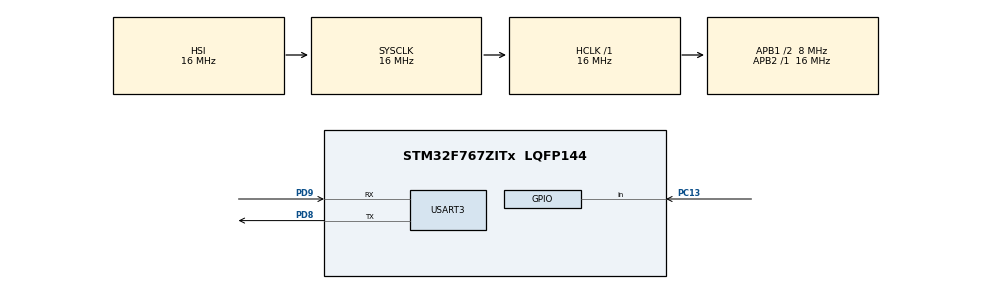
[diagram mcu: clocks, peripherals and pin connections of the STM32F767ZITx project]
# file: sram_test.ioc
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Mcu.Family=STM32F7
Mcu.Name=STM32F767ZITx
Mcu.Package=LQFP144
NVIC.PriorityGroup=NVIC_PRIORITYGROUP_4
PC13.Signal=GPIO_Input
PD8.Mode=Asynchronous
PD8.Signal=USART3_TX
PD9.Mode=Asynchronous
PD9.Signal=USART3_RX
ProjectManager.HeapSize=0x200
ProjectManager.StackSize=0x400
ProjectManager.TargetToolchain=MDK-ARM V5
RCC.48MHZClocksFreq_Value=24000000
RCC.AHBFreq_Value=16000000
RCC.APB1CLKDivider=RCC_HCLK_DIV2
RCC.APB1Freq_Value=8000000
RCC.APB1TimFreq_Value=16000000
RCC.APB2Freq_Value=16000000
RCC.APB2TimFreq_Value=16000000
RCC.CortexFreq_Value=16000000
RCC.HCLKFreq_Value=16000000
RCC.HSE_VALUE=16000000
RCC.HSI_VALUE=16000000
RCC.LSE_VALUE=32768
RCC.PLLMUL=RCC_PLL_MUL9
RCC.PRESCALERUSB=RCC_USBCLKSOURCE_PLL_DIV1_5
RCC.SYSCLKFreq_VALUE=16000000
RCC.SYSCLKSourceVirtual=RCC_SYSCLKSOURCE_PLLCLK
RCC.USBFreq_Value=96000000
RCC.VCOOutputFreq_Value=192000000
USART3.VirtualMode-Asynchronous=VM_ASYNC
board=NUCLEO-F767ZI

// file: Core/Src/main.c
/* USER CODE BEGIN Header */
/**
  ******************************************************************************
  * @file           : main.c
  * @brief          : Main program body
  ******************************************************************************
  * @attention
  *
  * <h2><center>&copy; Copyright (c) 2019 STMicroelectronics.
  * All rights reserved.</center></h2>
  *
  * This software component is licensed by ST under BSD 3-Clause license,
  * the "License"; You may not use this file except in compliance with the
  * License. You may obtain a copy of the License at:
  *                        opensource.org/licenses/BSD-3-Clause
  *
  ******************************************************************************
  */
/* USER CODE END Header */

#include "main.h"
#include "usart.h"
#include "gpio.h"

/* USER CODE BEGIN Includes */
#include "stm32f7xx_hal.h"
#include "stm32f7xx_hal_rcc.h"
#include "string.h"
/* USER CODE END Includes */

void SystemClock_Config(void);

int main(void)
{

  /* MCU Configuration--------------------------------------------------------*/

  /* Reset of all peripherals, Initializes the Flash interface and the Systick. */
  HAL_Init();

  /* Configure the system clock */
  SystemClock_Config();

  /* Initialize all configured peripherals */
  MX_GPIO_Init();
  MX_USART3_UART_Init();
  /* USER CODE BEGIN 2 */

	//Enable the PWR clock
	__HAL_RCC_PWR_CLK_ENABLE();
	//RCC_APB1PeriphClockCmd(RCC_APB1Periph_PWR, ENABLE);

	//Enable access to the backup domain
	HAL_PWR_EnableBkUpAccess();
	//PWR_BackupAccessCmd(ENABLE);

	//Enable backup SRAM Clock
	__HAL_RCC_BKPSRAM_CLK_ENABLE();
	//RCC_AHB1PeriphClockCmd(RCC_AHB1Periph_BKPSRAM, ENABLE);

	//Enable the Backup SRAM low power Regulator to retain it's content in VBAT mode
	HAL_PWREx_EnableBkUpReg();
	//PWR_BackupRegulatorCmd(ENABLE);

	//and you can write/read datas to sram (these codes from BKP_Domain codes in STM32F4xx_DSP_StdPeriph_Lib) (in my mcu stm32f417 BKPSRAM_BASE=0x40024000)

   // Write to Backup SRAM with 32-Bit Data
   //for (int i = 0x0; i < 0x100; i += 4) {
   //    *(__IO uint32_t *) (BKPSRAM_BASE + i) = i;
   //}

   // Check the written Data
   //for (int i = 0x0; i < 0x100; i += 4) {
   //       if ((*(__IO uint32_t *) (BKPSRAM_BASE + i)) != i){
   //           //errorindex++;
   //       }
   //}

	 	if(HAL_GPIO_ReadPin(GPIOC,GPIO_PIN_13)) //if user buttos is pressed set time/date
	{
		strcpy( (char*) (BKPSRAM_BASE), "Hello\n");
	}
	else
	{
		printf("%s", (volatile char*) BKPSRAM_BASE);
	}

  /* USER CODE END 2 */

  /* Infinite loop */
  while (1)
  {

  }
}

void SystemClock_Config(void)
{
  RCC_OscInitTypeDef RCC_OscInitStruct = {0};
  RCC_ClkInitTypeDef RCC_ClkInitStruct = {0};
  RCC_PeriphCLKInitTypeDef PeriphClkInitStruct = {0};

  /** Configure the main internal regulator output voltage
  */
  __HAL_RCC_PWR_CLK_ENABLE();
  __HAL_PWR_VOLTAGESCALING_CONFIG(PWR_REGULATOR_VOLTAGE_SCALE3);
  /** Initializes the CPU, AHB and APB busses clocks
  */
  RCC_OscInitStruct.OscillatorType = RCC_OSCILLATORTYPE_HSI;
  RCC_OscInitStruct.HSIState = RCC_HSI_ON;
  RCC_OscInitStruct.HSICalibrationValue = RCC_HSICALIBRATION_DEFAULT;
  RCC_OscInitStruct.PLL.PLLState = RCC_PLL_NONE;
  if (HAL_RCC_OscConfig(&RCC_OscInitStruct) != HAL_OK)
  {
    Error_Handler();
  }
  /** Initializes the CPU, AHB and APB busses clocks
  */
  RCC_ClkInitStruct.ClockType = RCC_CLOCKTYPE_HCLK|RCC_CLOCKTYPE_SYSCLK
                              |RCC_CLOCKTYPE_PCLK1|RCC_CLOCKTYPE_PCLK2;
  RCC_ClkInitStruct.SYSCLKSource = RCC_SYSCLKSOURCE_HSI;
  RCC_ClkInitStruct.AHBCLKDivider = RCC_SYSCLK_DIV1;
  RCC_ClkInitStruct.APB1CLKDivider = RCC_HCLK_DIV2;
  RCC_ClkInitStruct.APB2CLKDivider = RCC_HCLK_DIV1;

  if (HAL_RCC_ClockConfig(&RCC_ClkInitStruct, FLASH_LATENCY_0) != HAL_OK)
  {
    Error_Handler();
  }
  PeriphClkInitStruct.PeriphClockSelection = RCC_PERIPHCLK_USART3;
  PeriphClkInitStruct.Usart3ClockSelection = RCC_USART3CLKSOURCE_PCLK1;
  if (HAL_RCCEx_PeriphCLKConfig(&PeriphClkInitStruct) != HAL_OK)
  {
    Error_Handler();
  }
}

void Error_Handler(void)
{
}

/************************ (C) COPYRIGHT STMicroelectronics *****END OF FILE****/
